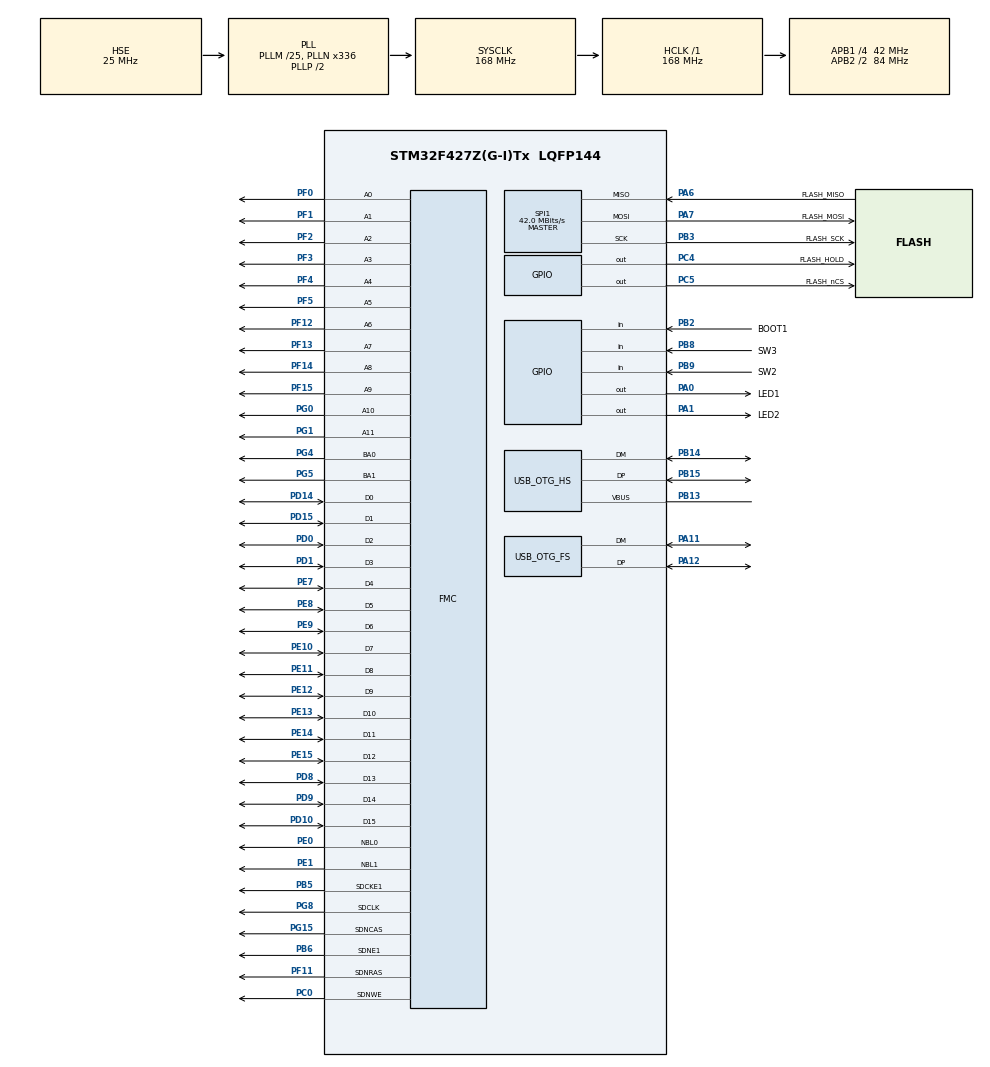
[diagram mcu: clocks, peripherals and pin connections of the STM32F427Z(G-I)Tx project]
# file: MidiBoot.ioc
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SH.FMC_D7_DA7.0=FMC_D7,sd-16b-d1
FMC.SDClockPeriod2=FMC_SDRAM_CLOCK_PERIOD_2
FMC.RCDDelay1=2
FMC.SDClockPeriod1=FMC_SDRAM_CLOCK_PERIOD_2
SH.FMC_A0.0=FMC_A0,12b-sda1
SPI1.VirtualType=VM_MASTER
PG4.Signal=FMC_A14_BA0
PG8.Signal=FMC_SDCLK
PG0.Signal=FMC_A10
FMC.LoadToActiveDelay1=2
PA6.GPIO_Label=FLASH_MISO
SH.FMC_D5_DA5.0=FMC_D5,sd-16b-d1
PB13.Signal=USB_OTG_HS_VBUS
RCC.SYSCLKSource=RCC_SYSCLKSOURCE_PLLCLK
SH.FMC_A15_BA1.0=FMC_BA1,FourSdramBanks1
SH.FMC_D9_DA9.0=FMC_D9,sd-16b-d1
SH.FMC_SDNWE.0=FMC_SDNWE,12b-sda1
SPI1.Direction=SPI_DIRECTION_2LINES
SH.FMC_D11_DA11.0=FMC_D11,sd-16b-d1
RCC.APB2TimFreq_Value=168000000
PB2/BOOT1.GPIO_Label=BOOT1
PB6.Signal=FMC_SDNE1
PH1/OSC_OUT.Signal=RCC_OSC_OUT
PB6.Mode=SdramChipSelect2_1
SPI1.CalculateBaudRate=42.0 MBits/s
PD0.Signal=FMC_D2_DA2
PD8.Signal=FMC_D13_DA13
PE1.Signal=FMC_NBL1
PB3.Mode=Full_Duplex_Master
FMC.SelfRefreshTime1=4
PC4.GPIO_Label=FLASH_HOLD
PE9.Signal=FMC_D6_DA6
PB14.Mode=Device_Only_FS
SH.FMC_A2.0=FMC_A2,12b-sda1
SH.FMC_D1_DA1.0=FMC_D1,sd-16b-d1
PF3.Signal=FMC_A3
PE10.Signal=FMC_D7_DA7
Mcu.Package=LQFP144
PB9.Signal=GPIO_Input
FMC.WriteRecoveryTime1=2
SH.FMC_A1.0=FMC_A1,12b-sda1
RCC.APB2CLKDivider=RCC_HCLK_DIV2
SH.FMC_SDCLK.0=FMC_SDCLK,12b-sda1
PF14.Signal=FMC_A8
RCC.APB1TimFreq_Value=84000000
FMC.RowCycleDelay2=6
FMC.RowCycleDelay1=6
PB13.Mode=Activate_VBUS_FS
PD15.Signal=FMC_D1_DA1
SH.FMC_D3_DA3.0=FMC_D3,sd-16b-d1
SH.FMC_A4.0=FMC_A4,12b-sda1
PG5.Signal=FMC_A15_BA1
SH.FMC_D10_DA10.0=FMC_D10,sd-16b-d1
PD1.Signal=FMC_D3_DA3
PC0.Signal=FMC_SDNWE
RCC.APB1CLKDivider=RCC_HCLK_DIV4
USB_OTG_HS.VirtualMode-Device_Only_FS=Device_Only_FS
PD10.Signal=FMC_D15_DA15
SH.FMC_A3.0=FMC_A3,12b-sda1
PB8.GPIO_Label=SW3
FMC.CASLatency1=FMC_SDRAM_CAS_LATENCY_3
SH.FMC_D15_DA15.0=FMC_D15,sd-16b-d1
PB14.Signal=USB_OTG_HS_DM
FMC.ReadBurst1=FMC_SDRAM_RBURST_ENABLE
SH.FMC_A6.0=FMC_A6,12b-sda1
FMC.ReadBurst2=FMC_SDRAM_RBURST_ENABLE
PE14.Signal=FMC_D11_DA11
PE15.Signal=FMC_D12_DA12
PE8.Signal=FMC_D5_DA5
SPI1.Mode=SPI_MODE_MASTER
PA1.GPIO_Label=LED2
PA0/WKUP.GPIO_Label=LED1
PF13.Signal=FMC_A7
PA13.Mode=Serial_Wire
SH.FMC_SDNCAS.0=FMC_SDNCAS,12b-sda1
PB5.Signal=FMC_SDCKE1
SH.FMC_A5.0=FMC_A5,12b-sda1
PA11.Signal=USB_OTG_FS_DM
ProjectManager.HeapSize=0x200
NVIC.PriorityGroup=NVIC_PRIORITYGROUP_4
PF4.Signal=FMC_A4
Mcu.Family=STM32F4
NVIC.OTG_HS_IRQn=true\:8\:0\:true\:false\:true\:true\:true
PA6.Mode=Full_Duplex_Master
SH.FMC_A8.0=FMC_A8,12b-sda1
RCC.CortexFreq_Value=168000000
SH.FMC_D14_DA14.0=FMC_D14,sd-16b-d1
VP_IWDG_VS_IWDG.Mode=IWDG_Activate
SH.FMC_NBL0.0=FMC_NBL0,Sd2ByteEnable1
SH.FMC_D6_DA6.0=FMC_D6,sd-16b-d1
PA11.Mode=Device_Only
PA0/WKUP.Signal=GPIO_Output
SH.FMC_A14_BA0.0=FMC_BA0,FourSdramBanks1
SH.FMC_A11.0=FMC_A11,12b-sda1
PB15.Signal=USB_OTG_HS_DP
PG15.Signal=FMC_SDNCAS
ProjectManager.StackSize=0x400
SH.FMC_A7.0=FMC_A7,12b-sda1
PA12.Signal=USB_OTG_FS_DP
PH0/OSC_IN.Mode=HSE-External-Oscillator
RCC.HCLKFreq_Value=168000000
SH.FMC_NBL1.0=FMC_NBL1,Sd2ByteEnable1
PF12.Signal=FMC_A6
SH.FMC_A10.0=FMC_A10,12b-sda1
RCC.AHBFreq_Value=168000000
RCC.HSE_VALUE=25000000
SH.FMC_D8_DA8.0=FMC_D8,sd-16b-d1
FMC.ExitSelfRefreshDelay1=6
FMC.RPDelay2=2
FMC.RPDelay1=2
SH.FMC_D2_DA2.0=FMC_D2,sd-16b-d1
PE13.Signal=FMC_D10_DA10
PA14.Mode=Serial_Wire
PB2/BOOT1.GPIO_PuPd=GPIO_PULLUP
PF11.Signal=FMC_SDNRAS
PB5.Mode=SdramChipSelect2_1
FMC.ReadPipeDelay1=FMC_SDRAM_RPIPE_DELAY_0
SH.FMC_SDNRAS.0=FMC_SDNRAS,12b-sda1
PH1/OSC_OUT.Mode=HSE-External-Oscillator
PA6.Signal=SPI1_MISO
SH.FMC_D0_DA0.0=FMC_D0,sd-16b-d1
IWDG.Reload=8*(30000/128)
USB_OTG_FS.VirtualMode=Device_Only
SH.FMC_A9.0=FMC_A9,12b-sda1
SH.FMC_D4_DA4.0=FMC_D4,sd-16b-d1
RCC.PLLSAIN=100
PF5.Signal=FMC_A5
PC5.Signal=GPIO_Output
PF0.Signal=FMC_A0
PE7.Signal=FMC_D4_DA4
PB3.GPIO_Label=FLASH_SCK
PA7.Mode=Full_Duplex_Master
PB9.GPIO_Label=SW2
PG1.Signal=FMC_A11
PC4.Signal=GPIO_Output
PD9.Signal=FMC_D14_DA14
PA13.Signal=SYS_JTMS-SWDIO
PB2/BOOT1.Signal=GPIO_Input
ProjectManager.TargetToolchain=MDK-ARM V5
SH.FMC_D13_DA13.0=FMC_D13,sd-16b-d1
PF2.Signal=FMC_A2
RCC.USBFreq_Value=48000000
PE11.Signal=FMC_D8_DA8
RCC.LSE_VALUE=32768
PA1.Signal=GPIO_Output
board=MidiBoot
RCC.VCOOutputFreq_Value=336000000
PB15.Mode=Device_Only_FS
PH0/OSC_IN.Signal=RCC_OSC_IN
RCC.APB2Freq_Value=84000000
SH.FMC_D12_DA12.0=FMC_D12,sd-16b-d1
PF15.Signal=FMC_A9
PF1.Signal=FMC_A1
Mcu.Name=STM32F427Z(G-I)Tx
PE0.Signal=FMC_NBL0
PE12.Signal=FMC_D9_DA9
PD14.Signal=FMC_D0_DA0
RCC.48MHZClocksFreq_Value=48000000
PB3.Signal=SPI1_SCK
RCC.SYSCLKFreq_VALUE=168000000
PA7.GPIO_Label=FLASH_MOSI
PA12.Mode=Device_Only
PC5.GPIO_Label=FLASH_nCS
PA14.Signal=SYS_JTCK-SWCLK
RCC.HSI_VALUE=16000000
RCC.PLLQ=7
RCC.PLLM=25
RCC.PLLN=336
IWDG.Prescaler=IWDG_PRESCALER_128
PB8.Signal=GPIO_Input
RCC.APB1Freq_Value=42000000
PA7.Signal=SPI1_MOSI

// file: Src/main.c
/* USER CODE BEGIN Header */
/**
  ******************************************************************************
  * @file           : main.c
  * @brief          : Main program body
  ******************************************************************************
  * @attention
  *
  * <h2><center>&copy; Copyright (c) 2020 STMicroelectronics.
  * All rights reserved.</center></h2>
  *
  * This software component is licensed by ST under Ultimate Liberty license
  * SLA0044, the "License"; You may not use this file except in compliance with
  * the License. You may obtain a copy of the License at:
  *                             www.st.com/SLA0044
  *
  ******************************************************************************
  */
/* USER CODE END Header */

#include "main.h"
#include "usb_device.h"

/* USER CODE BEGIN Includes */
#include "device.h"
#include "errorhandlers.h"
/* USER CODE END Includes */

IWDG_HandleTypeDef hiwdg;

SPI_HandleTypeDef hspi1;

#if !defined OWL_PRISM && !defined OWL_BIOSIGNALS && !defined OWL_NOCTUA
SDRAM_HandleTypeDef hsdram1;
#endif

/* USER CODE BEGIN PV */
/* Private variables ---------------------------------------------------------*/

/* USER CODE END PV */

void SystemClock_Config(void);
static void MX_GPIO_Init(void);
static void MX_FMC_Init(void);
static void MX_SPI1_Init(void);
static void MX_IWDG_Init(void);
/* USER CODE BEGIN PFP */
/* Private function prototypes -----------------------------------------------*/

void setup();
void SDRAM_Initialization_Sequence(SDRAM_HandleTypeDef *hsdram);
void loop(void);
void setMessage(const char* msg);

typedef  void (*pFunction)(void);

static int testMagic(){
  return *OWLBOOT_MAGIC_ADDRESS == OWLBOOT_MAGIC_NUMBER;
}

static int testLoop(){
  // Prevent reset cycles.
  // Check if we've been reset without zeroing the magic address,
  // which might indicate a corrupt firmware.
  return *OWLBOOT_MAGIC_ADDRESS == OWLBOOT_LOOP_NUMBER;
}

int testButton(){
#ifdef USE_BOOT1_PIN
  return !(BOOT1_GPIO_Port->IDR & BOOT1_Pin);
#else
  return 0;
#endif
}

static int testNoProgram(){
  return ((*(__IO uint32_t*)(APPLICATION_ADDRESS + 4)) & 0xFFF00000 ) != 0x08000000;
  /* Check Vector Table: Test if valid Reset_Handler pointer is programmed after APPLICATION_ADDRESS */
}

static int testWatchdogReset(){
  return __HAL_RCC_GET_FLAG(RCC_FLAG_IWDGRST) != RESET;
}

static int testPowerLowReset(){
  return __HAL_RCC_GET_FLAG(RCC_FLAG_LPWRRST) != RESET;
}

static int testBrownOutReset(){
  return __HAL_RCC_GET_FLAG(RCC_FLAG_BORRST) != RESET && // Power down or Brown out
    __HAL_RCC_GET_FLAG(RCC_FLAG_PORRST) == RESET; // Not power down

}

/* USER CODE END PFP */

int main(void)
{

  /* MCU Configuration--------------------------------------------------------*/

  /* Reset of all peripherals, Initializes the Flash interface and the Systick. */
  HAL_Init();

  /* Configure the system clock */
  SystemClock_Config();

  /* USER CODE BEGIN SysInit */

  MX_GPIO_Init();

  if(testMagic()){
    setMessage("Bootloader starting");
  }else if(testButton()){
    setMessage("Bootloader requested");
  }else if(testLoop()){
    error(RUNTIME_ERROR, "Unexpected reset");
  }else if(testWatchdogReset()){
    error(RUNTIME_ERROR, "Watchdog reset");
  }else if(testPowerLowReset()){
    error(RUNTIME_ERROR, "Low power reset");
  }else if(testBrownOutReset()){
    error(RUNTIME_ERROR, "Brown out reset");
  }else if(testNoProgram()){
    error(RUNTIME_ERROR, "No valid firmware");
  }else{
    // jump to application code

    /* Disable all interrupts */
    RCC->CIR = 0x00000000;

    /* Put marker in to prevent reset cycles */
    *OWLBOOT_MAGIC_ADDRESS = OWLBOOT_LOOP_NUMBER;

    /* Start watchdog */
    MX_IWDG_Init();

    /* Jump to user application */
    uint32_t JumpAddress = *(__IO uint32_t*) (APPLICATION_ADDRESS + 4);
    pFunction jumpToApplication = (pFunction) JumpAddress;
    /* Initialize user application's Stack Pointer */
    __set_MSP(*(__IO uint32_t*) APPLICATION_ADDRESS);
    jumpToApplication();
    for(;;);
  }
  /* Clear reset flags */
  __HAL_RCC_CLEAR_RESET_FLAGS();

  /* Clear magic */
  *OWLBOOT_MAGIC_ADDRESS = 0;

#if !defined OWL_PRISM && !defined OWL_BIOSIGNALS && !defined OWL_NOCTUA
  MX_FMC_Init();
  SDRAM_Initialization_Sequence(&hsdram1);
#endif

  /* USER CODE END SysInit */

  /* Initialize all configured peripherals */
  MX_SPI1_Init();
  MX_USB_DEVICE_Init();
  /* USER CODE BEGIN 2 */

  // Initialise
  setup();

  /* USER CODE END 2 */

  /* Infinite loop */
  /* USER CODE BEGIN WHILE */
  while (1)
  {
    loop();
    /* USER CODE END WHILE */
  }
}

void SystemClock_Config(void)
{
  RCC_OscInitTypeDef RCC_OscInitStruct = {0};
  RCC_ClkInitTypeDef RCC_ClkInitStruct = {0};

  /** Configure the main internal regulator output voltage
  */
  __HAL_RCC_PWR_CLK_ENABLE();
  __HAL_PWR_VOLTAGESCALING_CONFIG(PWR_REGULATOR_VOLTAGE_SCALE1);
  /** Initializes the CPU, AHB and APB busses clocks
  */
  RCC_OscInitStruct.OscillatorType = RCC_OSCILLATORTYPE_LSI|RCC_OSCILLATORTYPE_HSE;
  RCC_OscInitStruct.HSEState = RCC_HSE_ON;
  RCC_OscInitStruct.LSIState = RCC_LSI_ON;
  RCC_OscInitStruct.PLL.PLLState = RCC_PLL_ON;
  RCC_OscInitStruct.PLL.PLLSource = RCC_PLLSOURCE_HSE;
  RCC_OscInitStruct.PLL.PLLM = 25;
  RCC_OscInitStruct.PLL.PLLN = 336;
  RCC_OscInitStruct.PLL.PLLP = RCC_PLLP_DIV2;
  RCC_OscInitStruct.PLL.PLLQ = 7;
  if (HAL_RCC_OscConfig(&RCC_OscInitStruct) != HAL_OK)
  {
    Error_Handler();
  }
  /** Initializes the CPU, AHB and APB busses clocks
  */
  RCC_ClkInitStruct.ClockType = RCC_CLOCKTYPE_HCLK|RCC_CLOCKTYPE_SYSCLK
                              |RCC_CLOCKTYPE_PCLK1|RCC_CLOCKTYPE_PCLK2;
  RCC_ClkInitStruct.SYSCLKSource = RCC_SYSCLKSOURCE_PLLCLK;
  RCC_ClkInitStruct.AHBCLKDivider = RCC_SYSCLK_DIV1;
  RCC_ClkInitStruct.APB1CLKDivider = RCC_HCLK_DIV4;
  RCC_ClkInitStruct.APB2CLKDivider = RCC_HCLK_DIV2;

  if (HAL_RCC_ClockConfig(&RCC_ClkInitStruct, FLASH_LATENCY_5) != HAL_OK)
  {
    Error_Handler();
  }
}

static void MX_IWDG_Init(void)
{

  /* USER CODE BEGIN IWDG_Init 1 */
#ifdef USE_IWDG
  /* USER CODE END IWDG_Init 1 */
  hiwdg.Instance = IWDG;
  hiwdg.Init.Prescaler = IWDG_PRESCALER_128;
  hiwdg.Init.Reload = 8*32000/128; // 8 seconds
  if (HAL_IWDG_Init(&hiwdg) != HAL_OK)
  {
    Error_Handler();
  }
  /* USER CODE BEGIN IWDG_Init 2 */
#endif
  /* USER CODE END IWDG_Init 2 */

}

static void MX_SPI1_Init(void)
{

  /* SPI1 parameter configuration*/
  hspi1.Instance = SPI1;
  hspi1.Init.Mode = SPI_MODE_MASTER;
  hspi1.Init.Direction = SPI_DIRECTION_2LINES;
  hspi1.Init.DataSize = SPI_DATASIZE_8BIT;
  hspi1.Init.CLKPolarity = SPI_POLARITY_LOW;
  hspi1.Init.CLKPhase = SPI_PHASE_1EDGE;
  hspi1.Init.NSS = SPI_NSS_SOFT;
  hspi1.Init.BaudRatePrescaler = SPI_BAUDRATEPRESCALER_2;
  hspi1.Init.FirstBit = SPI_FIRSTBIT_MSB;
  hspi1.Init.TIMode = SPI_TIMODE_DISABLE;
  hspi1.Init.CRCCalculation = SPI_CRCCALCULATION_DISABLE;
  hspi1.Init.CRCPolynomial = 10;
  if (HAL_SPI_Init(&hspi1) != HAL_OK)
  {
    Error_Handler();
  }

}

/* FMC initialization function */
static void MX_FMC_Init(void)
{

  /* USER CODE BEGIN FMC_Init 0 */
#if !defined OWL_PRISM && !defined OWL_BIOSIGNALS && !defined OWL_NOCTUA
  /* USER CODE END FMC_Init 0 */

  FMC_SDRAM_TimingTypeDef SdramTiming = {0};

  /** Perform the SDRAM1 memory initialization sequence
  */
  hsdram1.Instance = FMC_SDRAM_DEVICE;
  /* hsdram1.Init */
  hsdram1.Init.SDBank = FMC_SDRAM_BANK2;
  hsdram1.Init.ColumnBitsNumber = FMC_SDRAM_COLUMN_BITS_NUM_8;
  hsdram1.Init.RowBitsNumber = FMC_SDRAM_ROW_BITS_NUM_12;
  hsdram1.Init.MemoryDataWidth = FMC_SDRAM_MEM_BUS_WIDTH_16;
  hsdram1.Init.InternalBankNumber = FMC_SDRAM_INTERN_BANKS_NUM_4;
  hsdram1.Init.CASLatency = FMC_SDRAM_CAS_LATENCY_3;
  hsdram1.Init.WriteProtection = FMC_SDRAM_WRITE_PROTECTION_DISABLE;
  hsdram1.Init.SDClockPeriod = FMC_SDRAM_CLOCK_PERIOD_2;
  hsdram1.Init.ReadBurst = FMC_SDRAM_RBURST_ENABLE;
  hsdram1.Init.ReadPipeDelay = FMC_SDRAM_RPIPE_DELAY_0;
  /* SdramTiming */
  SdramTiming.LoadToActiveDelay = 2;
  SdramTiming.ExitSelfRefreshDelay = 6;
  SdramTiming.SelfRefreshTime = 4;
  SdramTiming.RowCycleDelay = 6;
  SdramTiming.WriteRecoveryTime = 2;
  SdramTiming.RPDelay = 2;
  SdramTiming.RCDDelay = 2;

  if (HAL_SDRAM_Init(&hsdram1, &SdramTiming) != HAL_OK)
  {
    Error_Handler( );
  }

  /* USER CODE BEGIN FMC_Init 2 */
#endif
  /* USER CODE END FMC_Init 2 */
}

static void MX_GPIO_Init(void)
{
  GPIO_InitTypeDef GPIO_InitStruct = {0};

  /* GPIO Ports Clock Enable */
  __HAL_RCC_GPIOE_CLK_ENABLE();
  __HAL_RCC_GPIOC_CLK_ENABLE();
  __HAL_RCC_GPIOF_CLK_ENABLE();
  __HAL_RCC_GPIOH_CLK_ENABLE();
  __HAL_RCC_GPIOA_CLK_ENABLE();
  __HAL_RCC_GPIOB_CLK_ENABLE();
  __HAL_RCC_GPIOG_CLK_ENABLE();
  __HAL_RCC_GPIOD_CLK_ENABLE();

#ifdef LED1_Pin
  /*Configure GPIO pin Output Level */
  HAL_GPIO_WritePin(LED1_GPIO_Port, LED1_Pin, GPIO_PIN_RESET);
#endif
#ifdef LED2_Pin
  HAL_GPIO_WritePin(LED2_GPIO_Port, LED2_Pin, GPIO_PIN_RESET);
#endif

  /*Configure GPIO pin Output Level */
  HAL_GPIO_WritePin(GPIOB, FLASH_WP_Pin, GPIO_PIN_RESET);
  HAL_GPIO_WritePin(GPIOC, FLASH_HOLD_Pin|FLASH_nCS_Pin, GPIO_PIN_RESET);

#ifdef LED1_Pin
  /*Configure GPIO pins : LED1_Pin */
  GPIO_InitStruct.Pin = LED1_Pin;
  GPIO_InitStruct.Mode = GPIO_MODE_OUTPUT_PP;
  GPIO_InitStruct.Pull = GPIO_NOPULL;
  GPIO_InitStruct.Speed = GPIO_SPEED_FREQ_LOW;
  HAL_GPIO_Init(LED1_GPIO_Port, &GPIO_InitStruct);
#endif

#ifdef LED2_Pin
  /*Configure GPIO pins : LED2_Pin */
  GPIO_InitStruct.Pin = LED1_Pin|LED2_Pin;
  GPIO_InitStruct.Mode = GPIO_MODE_OUTPUT_PP;
  GPIO_InitStruct.Pull = GPIO_NOPULL;
  GPIO_InitStruct.Speed = GPIO_SPEED_FREQ_LOW;
  HAL_GPIO_Init(LED2_GPIO_Port, &GPIO_InitStruct);
#endif

  GPIO_InitStruct.Pin = FLASH_WP_Pin;
  GPIO_InitStruct.Mode = GPIO_MODE_OUTPUT_PP;
  GPIO_InitStruct.Pull = GPIO_NOPULL;
  GPIO_InitStruct.Speed = GPIO_SPEED_FREQ_LOW;
  HAL_GPIO_Init(GPIOB, &GPIO_InitStruct);

  /*Configure GPIO pins : FLASH_HOLD_Pin FLASH_nCS_Pin */
  GPIO_InitStruct.Pin = FLASH_HOLD_Pin|FLASH_nCS_Pin;
  GPIO_InitStruct.Mode = GPIO_MODE_OUTPUT_PP;
  GPIO_InitStruct.Pull = GPIO_NOPULL;
  GPIO_InitStruct.Speed = GPIO_SPEED_FREQ_LOW;
  HAL_GPIO_Init(GPIOC, &GPIO_InitStruct);

#ifdef USE_BOOT1_PIN
  /*Configure GPIO pin : BOOT1_Pin */
  GPIO_InitStruct.Pin = BOOT1_Pin;
  GPIO_InitStruct.Mode = GPIO_MODE_INPUT;
  GPIO_InitStruct.Pull = GPIO_PULLUP;
  HAL_GPIO_Init(BOOT1_GPIO_Port, &GPIO_InitStruct);
#endif

}

void Error_Handler(void)
{
  /* USER CODE BEGIN Error_Handler_Debug */
#ifdef DEBUG
  __asm__("BKPT");
#else
  NVIC_SystemReset();
#endif
  /* USER CODE END Error_Handler_Debug */
}

#ifdef  USE_FULL_ASSERT
/**
  * @brief  Reports the name of the source file and the source line number
  *         where the assert_param error has occurred.
  * @param  file: pointer to the source file name
  * @param  line: assert_param error line source number
  * @retval None
  */
void assert_failed(uint8_t *file, uint32_t line)
{
  /* USER CODE BEGIN 6 */
#ifdef DEBUG
  __asm__("BKPT");
#else
  NVIC_SystemReset();
#endif
  /* USER CODE END 6 */
}
#endif /* USE_FULL_ASSERT */

/************************ (C) COPYRIGHT STMicroelectronics *****END OF FILE****/
